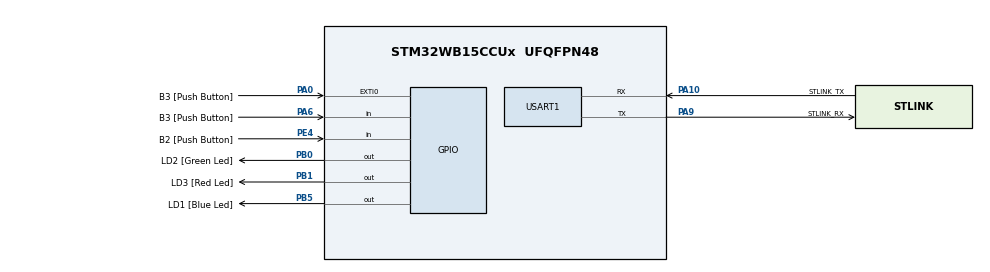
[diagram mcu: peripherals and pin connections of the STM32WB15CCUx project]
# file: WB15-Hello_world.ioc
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FREERTOS.BinarySemaphores01=semaphore_button,Static,myBinarySem01ControlBlock
FREERTOS.Tasks01=defaultTask,24,128,StartDefaultTask,Default,NULL,Dynamic,NULL,NULL
FREERTOS.configUSE_IDLE_HOOK=1
FREERTOS.configUSE_NEWLIB_REENTRANT=1
Mcu.Family=STM32WB
Mcu.Name=STM32WB15CCUx
Mcu.Package=UFQFPN48
NVIC.EXTI0_IRQn=true\:5\:0\:false\:false\:true\:true\:true\:true
NVIC.PriorityGroup=NVIC_PRIORITYGROUP_4
NVIC.TIM1_UP_IRQn=true\:15\:0\:false\:false\:true\:false\:false\:true
NVIC.TimeBase=TIM1_UP_IRQn
NVIC.TimeBaseIP=TIM1
OSC_IN.Mode=HSE-External-Oscillator
OSC_IN.Signal=RCC_OSC_IN
OSC_OUT.Mode=HSE-External-Oscillator
OSC_OUT.Signal=RCC_OSC_OUT
PA0.GPIO_Label=B3 [Push Button]
PA0.Signal=GPXTI0
PA10.GPIO_Label=STLINK_TX
PA10.GPIO_PuPd=GPIO_PULLUP
PA10.Mode=Asynchronous
PA10.Signal=USART1_RX
PA13.GPIO_Label=JTMS
PA13.Mode=Serial_Wire
PA13.Signal=SYS_JTMS-SWDIO
PA14.GPIO_Label=JTCK
PA14.Mode=Serial_Wire
PA14.Signal=SYS_JTCK-SWCLK
PA6.GPIO_Label=B3 [Push Button]
PA6.GPIO_PuPd=GPIO_PULLUP
PA6.Signal=GPIO_Input
PA9.GPIO_Label=STLINK_RX
PA9.GPIO_PuPd=GPIO_PULLUP
PA9.Mode=Asynchronous
PA9.Signal=USART1_TX
PB0.GPIO_Label=LD2 [Green Led]
PB0.Signal=GPIO_Output
PB1.GPIO_Label=LD3 [Red Led]
PB1.Signal=GPIO_Output
PB3.GPIO_Label=JTDO
PB3.Signal=SYS_JTDO-SWO
PB5.GPIO_Label=LD1 [Blue Led]
PB5.Signal=GPIO_Output
PC14-OSC32_IN.Mode=LSE-External-Oscillator
PC14-OSC32_IN.Signal=RCC_OSC32_IN
PC15-OSC32_OUT.Mode=LSE-External-Oscillator
PC15-OSC32_OUT.Signal=RCC_OSC32_OUT
PE4.GPIO_Label=B2 [Push Button]
PE4.GPIO_PuPd=GPIO_PULLUP
PE4.Signal=GPIO_Input
ProjectManager.HeapSize=0x200
ProjectManager.StackSize=0x400
ProjectManager.TargetToolchain=STM32CubeIDE
RCC.AHB2CLKDivider=RCC_SYSCLK_DIV2
RCC.AHBFreq_Value=64000000
RCC.APB1Freq_Value=64000000
RCC.APB1TimFreq_Value=64000000
RCC.APB2Freq_Value=64000000
RCC.APB2TimFreq_Value=64000000
RCC.APB3Freq_Value=16000000
RCC.CortexFreq_Value=64000000
RCC.HCLKFreq_Value=64000000
RCC.HSE_VALUE=32000000
RCC.HSI_VALUE=16000000
RCC.PLLN=32
RCC.SYSCLKFreq_VALUE=64000000
RCC.SYSCLKSource=RCC_SYSCLKSOURCE_PLLCLK
RCC.VCOOutputFreq_Value=128000000
RTC.Format=RTC_FORMAT_BIN
RTC.Hours=12
RTC.Minutes=34
RTC.Year=21
USART1.VirtualMode-Asynchronous=VM_ASYNC
VP_FREERTOS_VS_CMSIS_V2.Mode=CMSIS_V2
VP_RTC_VS_RTC_Activate.Mode=RTC_Enabled
VP_RTC_VS_RTC_Calendar.Mode=RTC_Calendar
VP_SYS_VS_tim1.Mode=TIM1
board=NUCLEO-WB15CC

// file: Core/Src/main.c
/* USER CODE BEGIN Header */
/**
  ******************************************************************************
  * @file           : main.c
  * @brief          : Main program body
  ******************************************************************************
  * @attention
  *
  * <h2><center>&copy; Copyright (c) 2021 STMicroelectronics.
  * All rights reserved.</center></h2>
  *
  * This software component is licensed by ST under BSD 3-Clause license,
  * the "License"; You may not use this file except in compliance with the
  * License. You may obtain a copy of the License at:
  *                        opensource.org/licenses/BSD-3-Clause
  *
  ******************************************************************************
  */
/* USER CODE END Header */
#include "main.h"
#include "cmsis_os.h"
#include "rtc.h"
#include "usart.h"
#include "gpio.h"

void SystemClock_Config(void);
void MX_FREERTOS_Init(void);

int main(void)
{

  /* MCU Configuration--------------------------------------------------------*/

  /* Reset of all peripherals, Initializes the Flash interface and the Systick. */
  HAL_Init();

  /* Configure the system clock */
  SystemClock_Config();

  /* Initialize all configured peripherals */
  MX_GPIO_Init();
  MX_USART1_UART_Init();
  MX_RTC_Init();

  /* Init scheduler */
  osKernelInitialize();  /* Call init function for freertos objects (in freertos.c) */
  MX_FREERTOS_Init();
  /* Start scheduler */
  osKernelStart();

  /* We should never get here as control is now taken by the scheduler */
  /* Infinite loop */
  while (1)
  {

  }
}

void SystemClock_Config(void)
{
  RCC_OscInitTypeDef RCC_OscInitStruct = {0};
  RCC_ClkInitTypeDef RCC_ClkInitStruct = {0};
  RCC_PeriphCLKInitTypeDef PeriphClkInitStruct = {0};

  /** Configure LSE Drive Capability
  */
  HAL_PWR_EnableBkUpAccess();
  __HAL_RCC_LSEDRIVE_CONFIG(RCC_LSEDRIVE_LOW);
  /** Initializes the RCC Oscillators according to the specified parameters
  * in the RCC_OscInitTypeDef structure.
  */
  RCC_OscInitStruct.OscillatorType = RCC_OSCILLATORTYPE_HSI|RCC_OSCILLATORTYPE_LSI1
                              |RCC_OSCILLATORTYPE_HSE|RCC_OSCILLATORTYPE_LSE
                              |RCC_OSCILLATORTYPE_MSI;
  RCC_OscInitStruct.HSEState = RCC_HSE_ON;
  RCC_OscInitStruct.LSEState = RCC_LSE_ON;
  RCC_OscInitStruct.HSIState = RCC_HSI_ON;
  RCC_OscInitStruct.MSIState = RCC_MSI_ON;
  RCC_OscInitStruct.HSICalibrationValue = RCC_HSICALIBRATION_DEFAULT;
  RCC_OscInitStruct.MSICalibrationValue = RCC_MSICALIBRATION_DEFAULT;
  RCC_OscInitStruct.MSIClockRange = RCC_MSIRANGE_6;
  RCC_OscInitStruct.LSIState = RCC_LSI_ON;
  RCC_OscInitStruct.PLL.PLLState = RCC_PLL_ON;
  RCC_OscInitStruct.PLL.PLLSource = RCC_PLLSOURCE_MSI;
  RCC_OscInitStruct.PLL.PLLM = RCC_PLLM_DIV1;
  RCC_OscInitStruct.PLL.PLLN = 32;
  RCC_OscInitStruct.PLL.PLLP = RCC_PLLP_DIV2;
  RCC_OscInitStruct.PLL.PLLR = RCC_PLLR_DIV2;
  RCC_OscInitStruct.PLL.PLLQ = RCC_PLLQ_DIV2;
  if (HAL_RCC_OscConfig(&RCC_OscInitStruct) != HAL_OK)
  {
    Error_Handler();
  }
  /** Configure the SYSCLKSource, HCLK, PCLK1 and PCLK2 clocks dividers
  */
  RCC_ClkInitStruct.ClockType = RCC_CLOCKTYPE_HCLK4|RCC_CLOCKTYPE_HCLK2
                              |RCC_CLOCKTYPE_HCLK|RCC_CLOCKTYPE_SYSCLK
                              |RCC_CLOCKTYPE_PCLK1|RCC_CLOCKTYPE_PCLK2;
  RCC_ClkInitStruct.SYSCLKSource = RCC_SYSCLKSOURCE_PLLCLK;
  RCC_ClkInitStruct.AHBCLKDivider = RCC_SYSCLK_DIV1;
  RCC_ClkInitStruct.APB1CLKDivider = RCC_HCLK_DIV1;
  RCC_ClkInitStruct.APB2CLKDivider = RCC_HCLK_DIV1;
  RCC_ClkInitStruct.AHBCLK2Divider = RCC_SYSCLK_DIV2;
  RCC_ClkInitStruct.AHBCLK4Divider = RCC_SYSCLK_DIV1;

  if (HAL_RCC_ClockConfig(&RCC_ClkInitStruct, FLASH_LATENCY_3) != HAL_OK)
  {
    Error_Handler();
  }
  /** Initializes the peripherals clocks
  */
  PeriphClkInitStruct.PeriphClockSelection = RCC_PERIPHCLK_SMPS|RCC_PERIPHCLK_RTC
                              |RCC_PERIPHCLK_USART1;
  PeriphClkInitStruct.Usart1ClockSelection = RCC_USART1CLKSOURCE_PCLK2;
  PeriphClkInitStruct.RTCClockSelection = RCC_RTCCLKSOURCE_LSI;
  PeriphClkInitStruct.SmpsClockSelection = RCC_SMPSCLKSOURCE_HSI;
  PeriphClkInitStruct.SmpsDivSelection = RCC_SMPSCLKDIV_RANGE1;
  if (HAL_RCCEx_PeriphCLKConfig(&PeriphClkInitStruct) != HAL_OK)
  {
    Error_Handler();
  }
  /** Enable MSI Auto calibration
  */
  HAL_RCCEx_EnableMSIPLLMode();
}

void HAL_TIM_PeriodElapsedCallback(TIM_HandleTypeDef *htim)
{
  if (htim->Instance == TIM1) {
    HAL_IncTick();
  }
}

void Error_Handler(void)
{
  __disable_irq();
  while (1)
  {
  }
}

/************************ (C) COPYRIGHT STMicroelectronics *****END OF FILE****/

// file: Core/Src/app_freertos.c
/* USER CODE BEGIN Header */
/**
  ******************************************************************************
  * File Name          : app_freertos.c
  * Description        : Code for freertos applications
  ******************************************************************************
  * @attention
  *
  * <h2><center>&copy; Copyright (c) 2021 STMicroelectronics.
  * All rights reserved.</center></h2>
  *
  * This software component is licensed by ST under Ultimate Liberty license
  * SLA0044, the "License"; You may not use this file except in compliance with
  * the License. You may obtain a copy of the License at:
  *                             www.st.com/SLA0044
  *
  ******************************************************************************
  */
/* USER CODE END Header */

#include "FreeRTOS.h"
#include "task.h"
#include "main.h"
#include "cmsis_os.h"

/* USER CODE BEGIN Includes */
#include "led.h"
#include "clock.h"
/* USER CODE END Includes */

typedef StaticSemaphore_t osStaticSemaphoreDef_t;

/* Definitions for defaultTask */
osThreadId_t defaultTaskHandle;
const osThreadAttr_t defaultTask_attributes = {
  .name = "defaultTask",
  .priority = (osPriority_t) osPriorityNormal,
  .stack_size = 128 * 4
};
/* Definitions for semaphore_button */
osSemaphoreId_t semaphore_buttonHandle;
osStaticSemaphoreDef_t myBinarySem01ControlBlock;
const osSemaphoreAttr_t semaphore_button_attributes = {
  .name = "semaphore_button",
  .cb_mem = &myBinarySem01ControlBlock,
  .cb_size = sizeof(myBinarySem01ControlBlock),
};

void StartDefaultTask(void *argument);

void MX_FREERTOS_Init(void); /* (MISRA C 2004 rule 8.1) */

/* Hook prototypes */
void vApplicationIdleHook(void);

/* USER CODE BEGIN 2 */
void vApplicationIdleHook( void )
{
   /* vApplicationIdleHook() will only be called if configUSE_IDLE_HOOK is set
   to 1 in FreeRTOSConfig.h. It will be called on each iteration of the idle
   task. It is essential that code added to this hook function never attempts
   to block in any way (for example, call xQueueReceive() with a block time
   specified, or call vTaskDelay()). If the application makes use of the
   vTaskDelete() API function (as this demo application does) then it is also
   important that vApplicationIdleHook() is permitted to return to its calling
   function, because it is the responsibility of the idle task to clean up
   memory allocated by the kernel to any task that has since been deleted. */

	// SysTick nor TIM can wake up CPU from STOP mode
	// HAL_PWR_EnterSTOPMode(PWR_MAINREGULATOR_ON, PWR_STOPENTRY_WFI);

	// HAL_PWR_EnterSLEEPMode(PWR_MAINREGULATOR_ON, PWR_STOPENTRY_WFI);
	// HAL_PWR_EnterSLEEPMode(PWR_LOWPOWERREGULATOR_ON, PWR_STOPENTRY_WFI);
}
/* USER CODE END 2 */

void MX_FREERTOS_Init(void) {

  /* Create the semaphores(s) */
  /* creation of semaphore_button */
  semaphore_buttonHandle = osSemaphoreNew(1, 1, &semaphore_button_attributes);

  /* Create the thread(s) */
  /* creation of defaultTask */
  defaultTaskHandle = osThreadNew(StartDefaultTask, NULL, &defaultTask_attributes);

}

void StartDefaultTask(void *argument)
{
  /* USER CODE BEGIN StartDefaultTask */
	struct tm time;

  /* Infinite loop */
  for(;;)
  {
	  osSemaphoreAcquire(semaphore_buttonHandle, osWaitForever);
	  time = time_get();
	  osDelay(BLINK_PAUSE_DELAY);
	  led_blink_count(time.tm_hour / 10, RED);
	  osDelay(BLINK_PAUSE_DELAY);
	  led_blink_count(time.tm_hour % 10, GREEN);
	  osDelay(BLINK_PAUSE_DELAY);
	  led_blink_count(time.tm_min / 10, BLUE);

	  // No minutes
	  // osDelay(BLINK_PAUSE_DELAY);
	  // led_blink_count(time.tm_min % 10, PURPLE);

	  osSemaphoreAcquire(semaphore_buttonHandle, 0);		// acquire semaphore if the button was pressed during LED blinking

	  // HAL_PWR_EnterSTOPMode(PWR_LOWPOWERREGULATOR_ON, PWR_STOPENTRY_WFI);
	  // HAL_PWR_EnterSTANDBYMode();

  }
  /* USER CODE END StartDefaultTask */
}

/* USER CODE BEGIN Application */
void HAL_GPIO_EXTI_Callback(uint16_t GPIO_Pin)
{
	osSemaphoreRelease(semaphore_buttonHandle);
}
/* USER CODE END Application */

/************************ (C) COPYRIGHT STMicroelectronics *****END OF FILE****/
